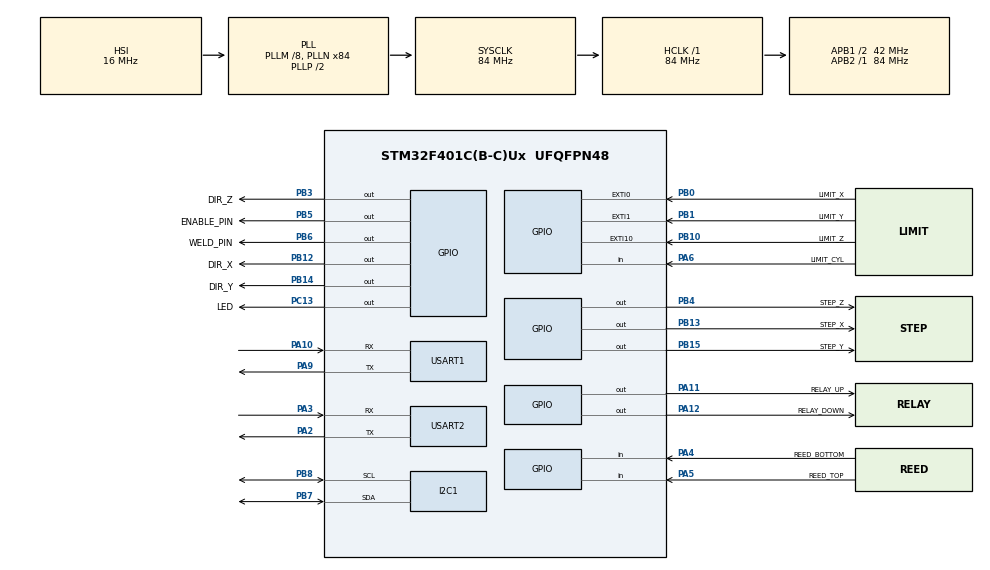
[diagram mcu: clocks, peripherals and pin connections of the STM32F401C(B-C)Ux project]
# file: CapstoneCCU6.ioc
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Dma.I2C1_RX.1.Direction=DMA_PERIPH_TO_MEMORY
Dma.I2C1_RX.1.FIFOMode=DMA_FIFOMODE_DISABLE
Dma.I2C1_RX.1.Instance=DMA1_Stream0
Dma.I2C1_RX.1.MemDataAlignment=DMA_MDATAALIGN_BYTE
Dma.I2C1_RX.1.MemInc=DMA_MINC_ENABLE
Dma.I2C1_RX.1.Mode=DMA_NORMAL
Dma.I2C1_RX.1.PeriphDataAlignment=DMA_PDATAALIGN_BYTE
Dma.I2C1_RX.1.PeriphInc=DMA_PINC_DISABLE
Dma.I2C1_RX.1.Priority=DMA_PRIORITY_LOW
Dma.Request0=USART1_TX
Dma.Request1=I2C1_RX
Dma.USART1_TX.0.Direction=DMA_MEMORY_TO_PERIPH
Dma.USART1_TX.0.FIFOMode=DMA_FIFOMODE_DISABLE
Dma.USART1_TX.0.Instance=DMA2_Stream7
Dma.USART1_TX.0.MemDataAlignment=DMA_MDATAALIGN_BYTE
Dma.USART1_TX.0.MemInc=DMA_MINC_ENABLE
Dma.USART1_TX.0.Mode=DMA_NORMAL
Dma.USART1_TX.0.PeriphDataAlignment=DMA_PDATAALIGN_BYTE
Dma.USART1_TX.0.PeriphInc=DMA_PINC_DISABLE
Dma.USART1_TX.0.Priority=DMA_PRIORITY_LOW
FREERTOS.Tasks01=defaultTask,0,128,StartDefaultTask,Default,NULL,Dynamic,NULL,NULL
I2C1.I2C_Mode=I2C_Fast
IWDG.Prescaler=IWDG_PRESCALER_32
IWDG.Reload=400
Mcu.Family=STM32F4
Mcu.Name=STM32F401C(B-C)Ux
Mcu.Package=UFQFPN48
NVIC.DMA1_Stream0_IRQn=true\:5\:0\:false\:false\:true\:true\:false\:true\:true
NVIC.DMA2_Stream7_IRQn=true\:5\:0\:false\:false\:true\:true\:false\:true\:true
NVIC.EXTI0_IRQn=true\:5\:0\:false\:false\:true\:true\:true\:true\:true
NVIC.EXTI15_10_IRQn=true\:5\:0\:false\:false\:true\:true\:true\:true\:true
NVIC.EXTI1_IRQn=true\:5\:0\:false\:false\:true\:true\:true\:true\:true
NVIC.I2C1_ER_IRQn=true\:5\:0\:false\:false\:true\:true\:true\:true\:true
NVIC.I2C1_EV_IRQn=true\:5\:0\:false\:false\:true\:true\:true\:true\:true
NVIC.PriorityGroup=NVIC_PRIORITYGROUP_4
NVIC.TIM1_TRG_COM_TIM11_IRQn=true\:15\:0\:false\:false\:true\:false\:false\:true\:true
NVIC.TIM2_IRQn=true\:5\:0\:false\:false\:true\:true\:true\:true\:true
NVIC.TIM3_IRQn=true\:5\:0\:false\:false\:true\:true\:true\:true\:true
NVIC.TIM4_IRQn=true\:5\:0\:false\:false\:true\:true\:true\:true\:true
NVIC.TIM5_IRQn=true\:5\:0\:false\:false\:true\:true\:true\:true\:true
NVIC.TimeBase=TIM1_TRG_COM_TIM11_IRQn
NVIC.TimeBaseIP=TIM11
NVIC.USART1_IRQn=true\:5\:0\:false\:false\:true\:true\:true\:true\:true
NVIC.USART2_IRQn=true\:5\:0\:false\:false\:true\:true\:true\:true\:true
PA10.Mode=Asynchronous
PA10.Signal=USART1_RX
PA11.GPIO_Label=RELAY_UP
PA11.Signal=GPIO_Output
PA12.GPIO_Label=RELAY_DOWN
PA12.Signal=GPIO_Output
PA13.Mode=Serial_Wire
PA13.Signal=SYS_JTMS-SWDIO
PA14.Mode=Serial_Wire
PA14.Signal=SYS_JTCK-SWCLK
PA2.Mode=Asynchronous
PA2.Signal=USART2_TX
PA3.Mode=Asynchronous
PA3.Signal=USART2_RX
PA4.GPIO_Label=REED_BOTTOM
PA4.Signal=GPIO_Input
PA5.GPIO_Label=REED_TOP
PA5.Signal=GPIO_Input
PA6.GPIO_Label=LIMIT_CYL
PA6.Signal=GPIO_Input
PA9.Mode=Asynchronous
PA9.Signal=USART1_TX
PB0.GPIO_Label=LIMIT_X
PB0.Signal=GPXTI0
PB1.GPIO_Label=LIMIT_Y
PB1.Signal=GPXTI1
PB10.GPIO_Label=LIMIT_Z
PB10.Signal=GPXTI10
PB12.GPIO_Label=DIR_X
PB12.Signal=GPIO_Output
PB13.GPIO_Label=STEP_X
PB13.Signal=GPIO_Output
PB14.GPIO_Label=DIR_Y
PB14.Signal=GPIO_Output
PB15.GPIO_Label=STEP_Y
PB15.GPIO_ModeDefaultOutputPP=GPIO_MODE_OUTPUT_PP
PB15.GPIO_PuPd=GPIO_NOPULL
PB15.Signal=GPIO_Output
PB3.GPIO_Label=DIR_Z
PB3.Signal=GPIO_Output
PB4.GPIO_Label=STEP_Z
PB4.Signal=GPIO_Output
PB5.GPIO_Label=ENABLE_PIN
PB5.Signal=GPIO_Output
PB6.GPIO_Label=WELD_PIN
PB6.Signal=GPIO_Output
PB7.Mode=I2C
PB7.Signal=I2C1_SDA
PB8.Mode=I2C
PB8.Signal=I2C1_SCL
PC13-ANTI_TAMP.GPIO_Label=LED
PC13-ANTI_TAMP.Signal=GPIO_Output
PH0\ -\ OSC_IN.Mode=HSE-External-Oscillator
PH0\ -\ OSC_IN.Signal=RCC_OSC_IN
PH1\ -\ OSC_OUT.Mode=HSE-External-Oscillator
PH1\ -\ OSC_OUT.Signal=RCC_OSC_OUT
ProjectManager.HeapSize=0x200
ProjectManager.StackSize=0x400
ProjectManager.TargetToolchain=STM32CubeIDE
RCC.48MHZClocksFreq_Value=42000000
RCC.AHBFreq_Value=84000000
RCC.APB1CLKDivider=RCC_HCLK_DIV2
RCC.APB1Freq_Value=42000000
RCC.APB1TimFreq_Value=84000000
RCC.APB2Freq_Value=84000000
RCC.APB2TimFreq_Value=84000000
RCC.CortexFreq_Value=84000000
RCC.HCLKFreq_Value=84000000
RCC.HSE_VALUE=25000000
RCC.HSI_VALUE=16000000
RCC.LSE_VALUE=32768
RCC.PLLM=8
RCC.PLLN=84
RCC.SYSCLKFreq_VALUE=84000000
RCC.SYSCLKSource=RCC_SYSCLKSOURCE_PLLCLK
RCC.VCOOutputFreq_Value=168000000
TIM2.AutoReloadPreload=TIM_AUTORELOAD_PRELOAD_ENABLE
TIM2.Period=4000
TIM2.Prescaler=21-1
TIM3.AutoReloadPreload=TIM_AUTORELOAD_PRELOAD_ENABLE
TIM3.Period=4000
TIM3.Prescaler=21-1
TIM4.AutoReloadPreload=TIM_AUTORELOAD_PRELOAD_ENABLE
TIM4.Period=4000
TIM4.Prescaler=21-1
TIM5.Period=1
TIM5.Prescaler=84-1
USART1.VirtualMode=VM_ASYNC
USART2.VirtualMode=VM_ASYNC
VP_FREERTOS_VS_CMSIS_V1.Mode=CMSIS_V1
VP_IWDG_VS_IWDG.Mode=IWDG_Activate
VP_SYS_VS_tim11.Mode=TIM11
VP_TIM2_VS_ClockSourceINT.Mode=Internal
VP_TIM3_VS_ClockSourceINT.Mode=Internal
VP_TIM4_VS_ClockSourceINT.Mode=Internal
VP_TIM5_VS_ClockSourceINT.Mode=Internal
VP_TIM5_VS_OPM.Mode=OPM_bit
board=custom

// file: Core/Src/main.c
/* USER CODE BEGIN Header */
/**
  ******************************************************************************
  * @file           : main.c
  * @brief          : Main program body
  ******************************************************************************
  * @attention
  *
  * Copyright (c) 2026 STMicroelectronics.
  * All rights reserved.
  *
  * This software is licensed under terms that can be found in the LICENSE file
  * in the root directory of this software component.
  * If no LICENSE file comes with this software, it is provided AS-IS.
  *
  ******************************************************************************
  */
/* USER CODE END Header */
#include "main.h"
#include "cmsis_os.h"
#include "dma.h"
#include "i2c.h"
#include "iwdg.h"
#include "tim.h"
#include "usart.h"
#include "gpio.h"

/* USER CODE BEGIN Includes */
#include "MachineApp.h"
/* USER CODE END Includes */

void SystemClock_Config(void);
void MX_FREERTOS_Init(void);

int main(void)
{

  /* MCU Configuration--------------------------------------------------------*/

  /* Reset of all peripherals, Initializes the Flash interface and the Systick. */
  HAL_Init();

  /* Configure the system clock */
  SystemClock_Config();

  /* Initialize all configured peripherals */
  MX_GPIO_Init();
  MX_DMA_Init();
  MX_TIM2_Init();
  MX_USART1_UART_Init();
  MX_TIM3_Init();
  MX_TIM4_Init();
  MX_IWDG_Init();
  MX_USART2_UART_Init();
  MX_I2C1_Init();
  MX_TIM5_Init();
  /* USER CODE BEGIN 2 */
  MachineApp_Init();
  /* USER CODE END 2 */

  /* Call init function for freertos objects (in cmsis_os2.c) */
  MX_FREERTOS_Init();

  /* Start scheduler */
  osKernelStart();

  /* We should never get here as control is now taken by the scheduler */

  /* Infinite loop */
  while (1)
  {

  }
}

void SystemClock_Config(void)
{
  RCC_OscInitTypeDef RCC_OscInitStruct = {0};
  RCC_ClkInitTypeDef RCC_ClkInitStruct = {0};

  /** Configure the main internal regulator output voltage
  */
  __HAL_RCC_PWR_CLK_ENABLE();
  __HAL_PWR_VOLTAGESCALING_CONFIG(PWR_REGULATOR_VOLTAGE_SCALE2);

  /** Initializes the RCC Oscillators according to the specified parameters
  * in the RCC_OscInitTypeDef structure.
  */
  RCC_OscInitStruct.OscillatorType = RCC_OSCILLATORTYPE_HSI|RCC_OSCILLATORTYPE_LSI;
  RCC_OscInitStruct.HSIState = RCC_HSI_ON;
  RCC_OscInitStruct.HSICalibrationValue = RCC_HSICALIBRATION_DEFAULT;
  RCC_OscInitStruct.LSIState = RCC_LSI_ON;
  RCC_OscInitStruct.PLL.PLLState = RCC_PLL_ON;
  RCC_OscInitStruct.PLL.PLLSource = RCC_PLLSOURCE_HSI;
  RCC_OscInitStruct.PLL.PLLM = 8;
  RCC_OscInitStruct.PLL.PLLN = 84;
  RCC_OscInitStruct.PLL.PLLP = RCC_PLLP_DIV2;
  RCC_OscInitStruct.PLL.PLLQ = 4;
  if (HAL_RCC_OscConfig(&RCC_OscInitStruct) != HAL_OK)
  {
    Error_Handler();
  }

  /** Initializes the CPU, AHB and APB buses clocks
  */
  RCC_ClkInitStruct.ClockType = RCC_CLOCKTYPE_HCLK|RCC_CLOCKTYPE_SYSCLK
                              |RCC_CLOCKTYPE_PCLK1|RCC_CLOCKTYPE_PCLK2;
  RCC_ClkInitStruct.SYSCLKSource = RCC_SYSCLKSOURCE_PLLCLK;
  RCC_ClkInitStruct.AHBCLKDivider = RCC_SYSCLK_DIV1;
  RCC_ClkInitStruct.APB1CLKDivider = RCC_HCLK_DIV2;
  RCC_ClkInitStruct.APB2CLKDivider = RCC_HCLK_DIV1;

  if (HAL_RCC_ClockConfig(&RCC_ClkInitStruct, FLASH_LATENCY_2) != HAL_OK)
  {
    Error_Handler();
  }
}

//void HAL_TIM_PeriodElapsedCallback(TIM_HandleTypeDef *htim)
//{
//  /* USER CODE BEGIN Callback 0 */
////////
//  /* USER CODE END Callback 0 */
//  if (htim->Instance == TIM11)
//  {
//    HAL_IncTick();
//  }
//  /* USER CODE BEGIN Callback 1 */
////////
//  /* USER CODE END Callback 1 */
//}

void Error_Handler(void)
{
  __disable_irq();
  while (1)
  {
  }
}

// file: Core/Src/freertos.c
/* USER CODE BEGIN Header */
/**
  ******************************************************************************
  * File Name          : freertos.c
  * Description        : Code for freertos applications
  ******************************************************************************
  * @attention
  *
  * Copyright (c) 2026 STMicroelectronics.
  * All rights reserved.
  *
  * This software is licensed under terms that can be found in the LICENSE file
  * in the root directory of this software component.
  * If no LICENSE file comes with this software, it is provided AS-IS.
  *
  ******************************************************************************
  */
/* USER CODE END Header */

#include "FreeRTOS.h"
#include "task.h"
#include "main.h"
#include "cmsis_os.h"

/* USER CODE BEGIN Includes */
#include "MachineApp.h"
/* USER CODE END Includes */

osThreadId defaultTaskHandle;

void StartDefaultTask(void const * argument);

void MX_FREERTOS_Init(void); /* (MISRA C 2004 rule 8.1) */

/* GetIdleTaskMemory prototype (linked to static allocation support) */
void vApplicationGetIdleTaskMemory( StaticTask_t **ppxIdleTaskTCBBuffer, StackType_t **ppxIdleTaskStackBuffer, uint32_t *pulIdleTaskStackSize );

/* USER CODE BEGIN GET_IDLE_TASK_MEMORY */
static StaticTask_t xIdleTaskTCBBuffer;
static StackType_t xIdleStack[configMINIMAL_STACK_SIZE];

void vApplicationGetIdleTaskMemory( StaticTask_t **ppxIdleTaskTCBBuffer, StackType_t **ppxIdleTaskStackBuffer, uint32_t *pulIdleTaskStackSize )
{
  *ppxIdleTaskTCBBuffer = &xIdleTaskTCBBuffer;
  *ppxIdleTaskStackBuffer = &xIdleStack[0];
  *pulIdleTaskStackSize = configMINIMAL_STACK_SIZE;
  /* place for user code */
}
/* USER CODE END GET_IDLE_TASK_MEMORY */

void MX_FREERTOS_Init(void) {

  /* Create the thread(s) */
  /* definition and creation of defaultTask */
  osThreadDef(defaultTask, StartDefaultTask, osPriorityNormal, 0, 128);
  defaultTaskHandle = osThreadCreate(osThread(defaultTask), NULL);

}

void StartDefaultTask(void const * argument)
{
  /* USER CODE BEGIN StartDefaultTask */
  /* Infinite loop */
  for(;;)
  {
	  MachineApp_Loop();
    osDelay(1);
  }
  /* USER CODE END StartDefaultTask */
}
